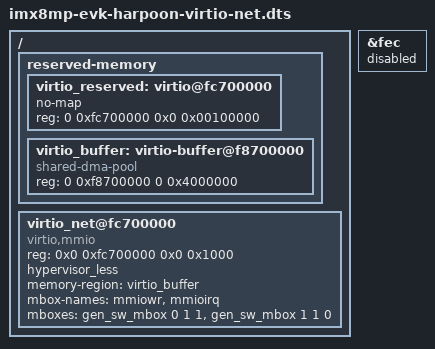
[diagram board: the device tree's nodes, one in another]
// SPDX-License-Identifier: (GPL-2.0+ OR MIT)
/*
 * Copyright 2023 NXP
 */

/dts-v1/;
#include "imx8mp-evk-root.dts"
#include "imx8mp-generic-mbox.dtsi"

/ {
	reserved-memory {
		#address-cells = <2>;
		#size-cells = <2>;
		ranges;

		virtio_reserved: virtio@fc700000 {
			no-map;
			reg = <0 0xfc700000 0x0 0x00100000>;
		};

		virtio_buffer: virtio-buffer@f8700000 {
			compatible = "shared-dma-pool";
			reg = <0 0xf8700000 0 0x4000000>;
		};
	};

	virtio_net@fc700000 {
		compatible = "virtio,mmio";
		reg = <0x0 0xfc700000 0x0 0x1000>;
		hypervisor_less;
		memory-region = <&virtio_buffer>;
		mbox-names = "mmiowr", "mmioirq";
		mboxes = <&gen_sw_mbox 0 1 1		/* TX channel with ACK */
			  &gen_sw_mbox 1 1 0>;		/* RX channel without ACK */
	};
};

&fec {
	status = "disabled";
};
